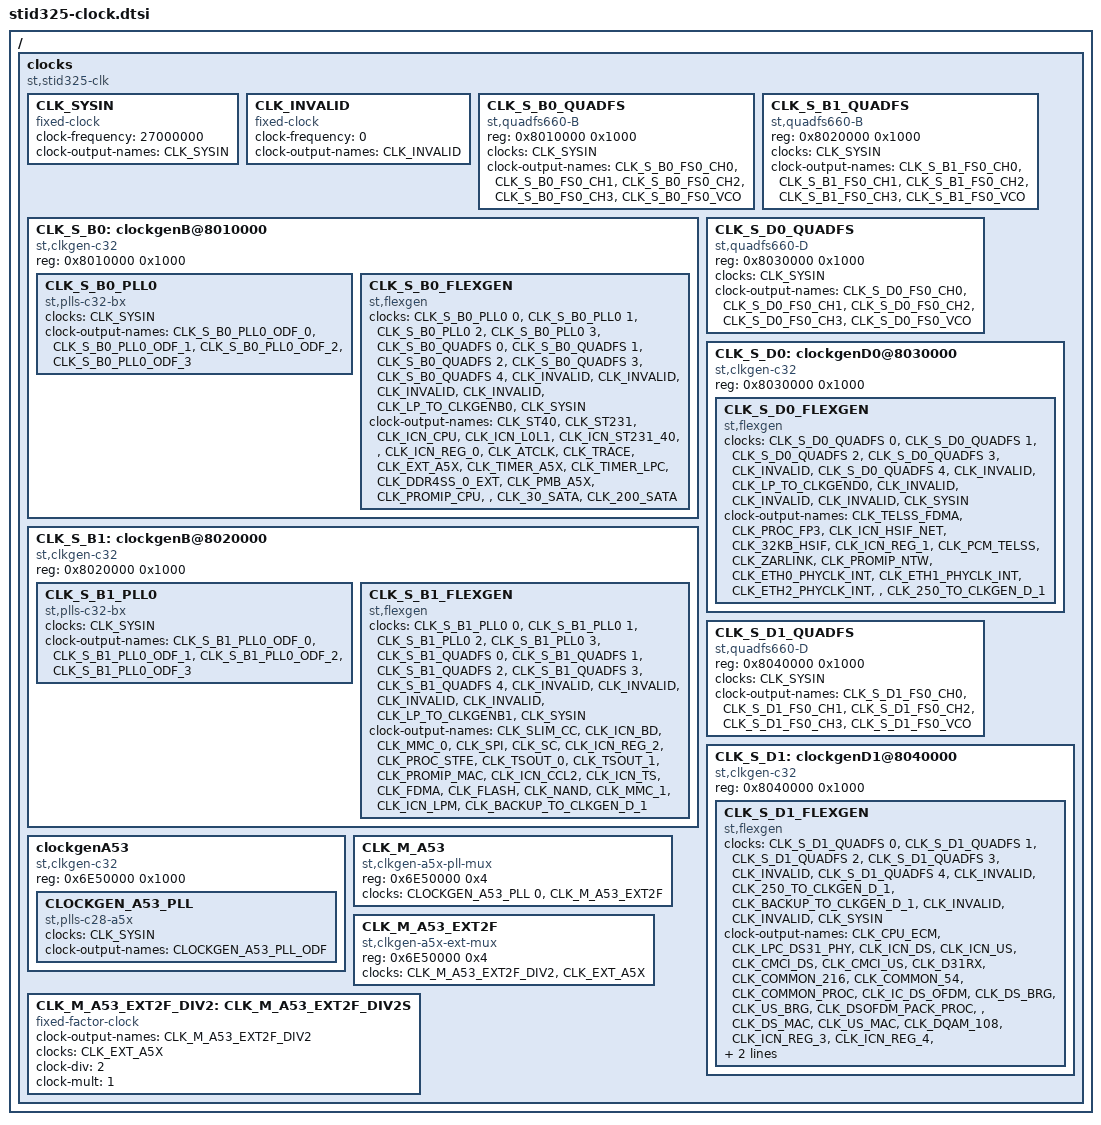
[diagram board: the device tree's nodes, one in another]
/*
 * Copyright (C) 2015 STMicroelectronics R&D Limited
 * Author: Giuseppe Condorelli <giuseppe.condorelli@st.com>
 *
 * This program is free software; you can redistribute it and/or modify
 * it under the terms of the GNU General Public License version 2 as
 * published by the Free Software Foundation.
 */

#include "stid325-clk-refs.h"

/ {
	clocks {
		#address-cells = <1>;
		#size-cells = <1>;
		ranges;
		compatible = "st,stid325-clk", "simple-bus";

		/*
		 * Fixed 27MHz oscillator inputs to SoC
		 */
		CLK_SYSIN: CLK_SYSIN {
			#clock-cells = <0>;
			compatible = "fixed-clock";
			clock-frequency = <27000000>;
			clock-output-names = "CLK_SYSIN";
		};

		/*
		 * Fixed clock added to act as parent for flexigen parents
		 * for unused values in the multiplexer registers
		 */
		CLK_INVALID: CLK_INVALID {
			#clock-cells = <0>;
			compatible = "fixed-clock";
			clock-frequency = <0>;
			clock-output-names = "CLK_INVALID";
		};

		CLK_S_B0_QUADFS: CLK_S_B0_QUADFS {
			compatible = "st,quadfs660-B", "st,quadfs";
			reg = <0x8010000 0x1000>;

			#clock-cells = <1>;
			clocks = <&CLK_SYSIN>;
			clock-output-names = "CLK_S_B0_FS0_CH0",
					     "CLK_S_B0_FS0_CH1",
					     "CLK_S_B0_FS0_CH2",
					     "CLK_S_B0_FS0_CH3",
					     "CLK_S_B0_FS0_VCO";
		};

		CLK_S_B0: clockgenB@8010000 {
			compatible = "st,clkgen-c32";
			reg = <0x8010000 0x1000>;

			CLK_S_B0_PLL0: CLK_S_B0_PLL0 {
				compatible = "st,plls-c32-bx", "st,clkgen-plls-c32";

				#clock-cells = <1>;
				clocks = <&CLK_SYSIN>;
				clock-output-names = "CLK_S_B0_PLL0_ODF_0",
						     "CLK_S_B0_PLL0_ODF_1",
						     "CLK_S_B0_PLL0_ODF_2",
						     "CLK_S_B0_PLL0_ODF_3";
			};

			CLK_S_B0_FLEXGEN: CLK_S_B0_FLEXGEN {
				compatible = "st,flexgen";

				#clock-cells = <1>;

				clocks = <&CLK_S_B0_PLL0 0>,
					 <&CLK_S_B0_PLL0 1>,
					 <&CLK_S_B0_PLL0 2>,
					 <&CLK_S_B0_PLL0 3>,
					 <&CLK_S_B0_QUADFS 0>,
					 <&CLK_S_B0_QUADFS 1>,
					 <&CLK_S_B0_QUADFS 2>,
					 <&CLK_S_B0_QUADFS 3>,
					 <&CLK_S_B0_QUADFS 4>,
					 <&CLK_INVALID>,
					 <&CLK_INVALID>,
					 <&CLK_INVALID>,
					 <&CLK_INVALID>,
					 <&CLK_LP_TO_CLKGENB0>,
					 <&CLK_SYSIN>;

				clock-output-names = "CLK_ST40",
						     "CLK_ST231",
						     "CLK_ICN_CPU",
						     "CLK_ICN_L0L1",
						     "CLK_ICN_ST231_40",
						     "",
						     "CLK_ICN_REG_0",
						     "CLK_ATCLK",
						     "CLK_TRACE",
						     "CLK_EXT_A5X",
						     "CLK_TIMER_A5X",
						     "CLK_TIMER_LPC",
						     "CLK_DDR4SS_0_EXT",
						     "CLK_PMB_A5X",
						     "CLK_PROMIP_CPU",
						     "",
						     "CLK_30_SATA",
						     "CLK_200_SATA";
			};
		};

		CLK_S_B1_QUADFS: CLK_S_B1_QUADFS {
			compatible = "st,quadfs660-B", "st,quadfs";
			reg = <0x8020000 0x1000>;

			#clock-cells = <1>;
			clocks = <&CLK_SYSIN>;
			clock-output-names = "CLK_S_B1_FS0_CH0",
					     "CLK_S_B1_FS0_CH1",
					     "CLK_S_B1_FS0_CH2",
					     "CLK_S_B1_FS0_CH3",
					     "CLK_S_B1_FS0_VCO";
		};

		CLK_S_B1: clockgenB@8020000 {
			compatible = "st,clkgen-c32";
			reg = <0x8020000 0x1000>;

			CLK_S_B1_PLL0: CLK_S_B1_PLL0 {
				compatible = "st,plls-c32-bx", "st,clkgen-plls-c32";

				#clock-cells = <1>;
				clocks = <&CLK_SYSIN>;
				clock-output-names = "CLK_S_B1_PLL0_ODF_0",
						     "CLK_S_B1_PLL0_ODF_1",
						     "CLK_S_B1_PLL0_ODF_2",
						     "CLK_S_B1_PLL0_ODF_3";
			};

			CLK_S_B1_FLEXGEN: CLK_S_B1_FLEXGEN {
				compatible = "st,flexgen";

				#clock-cells = <1>;

				clocks = <&CLK_S_B1_PLL0 0>,
					 <&CLK_S_B1_PLL0 1>,
					 <&CLK_S_B1_PLL0 2>,
					 <&CLK_S_B1_PLL0 3>,
					 <&CLK_S_B1_QUADFS 0>,
					 <&CLK_S_B1_QUADFS 1>,
					 <&CLK_S_B1_QUADFS 2>,
					 <&CLK_S_B1_QUADFS 3>,
					 <&CLK_S_B1_QUADFS 4>,
					 <&CLK_INVALID>,
					 <&CLK_INVALID>,
					 <&CLK_INVALID>,
					 <&CLK_INVALID>,
					 <&CLK_LP_TO_CLKGENB1>,
					 <&CLK_SYSIN>;

				clock-output-names = "CLK_SLIM_CC",
						     "CLK_ICN_BD",
						     "CLK_MMC_0",
						     "CLK_SPI",
						     "CLK_SC",
						     "CLK_ICN_REG_2",
						     "CLK_PROC_STFE",
						     "CLK_TSOUT_0",
						     "CLK_TSOUT_1",
						     "CLK_PROMIP_MAC",
						     "CLK_ICN_CCL2",
						     "CLK_ICN_TS",
						     "CLK_FDMA",
						     "CLK_FLASH",
						     "CLK_NAND",
						     "CLK_MMC_1",
						     "CLK_ICN_LPM",
						     "CLK_BACKUP_TO_CLKGEN_D_1";
			};
		};

		CLK_S_D0_QUADFS: CLK_S_D0_QUADFS {
			compatible = "st,quadfs660-D", "st,quadfs";
			reg = <0x8030000 0x1000>;

			#clock-cells = <1>;
			clocks = <&CLK_SYSIN>;
			clock-output-names = "CLK_S_D0_FS0_CH0",
					     "CLK_S_D0_FS0_CH1",
					     "CLK_S_D0_FS0_CH2",
					     "CLK_S_D0_FS0_CH3",
					     "CLK_S_D0_FS0_VCO";
		};

		CLK_S_D0: clockgenD0@8030000 {
			compatible = "st,clkgen-c32";
			reg = <0x8030000 0x1000>;

			CLK_S_D0_FLEXGEN: CLK_S_D0_FLEXGEN {
				compatible = "st,flexgen";
				#clock-cells = <1>;

				clocks = <&CLK_S_D0_QUADFS 0>,
					 <&CLK_S_D0_QUADFS 1>,
					 <&CLK_S_D0_QUADFS 2>,
					 <&CLK_S_D0_QUADFS 3>,
					 <&CLK_INVALID>,
					 <&CLK_S_D0_QUADFS 4>,
					 <&CLK_INVALID>,
					 <&CLK_LP_TO_CLKGEND0>,
					 <&CLK_INVALID>,
					 <&CLK_INVALID>,
					 <&CLK_INVALID>,
					 <&CLK_SYSIN>;

				clock-output-names = "CLK_TELSS_FDMA",
						     "CLK_PROC_FP3",
						     "CLK_ICN_HSIF_NET",
						     "CLK_32KB_HSIF",
						     "CLK_ICN_REG_1",
						     "CLK_PCM_TELSS",
						     "CLK_ZARLINK",
						     "CLK_PROMIP_NTW",
						     "CLK_ETH0_PHYCLK_INT",
						     "CLK_ETH1_PHYCLK_INT",
						     "CLK_ETH2_PHYCLK_INT",
						     "",
						     "CLK_250_TO_CLKGEN_D_1";
			};
		};

		CLK_S_D1_QUADFS: CLK_S_D1_QUADFS {
			compatible = "st,quadfs660-D", "st,quadfs";
			reg = <0x8040000 0x1000>;

			#clock-cells = <1>;
			clocks = <&CLK_SYSIN>;
			clock-output-names = "CLK_S_D1_FS0_CH0",
					     "CLK_S_D1_FS0_CH1",
					     "CLK_S_D1_FS0_CH2",
					     "CLK_S_D1_FS0_CH3",
					     "CLK_S_D1_FS0_VCO";
		};

		CLK_S_D1: clockgenD1@8040000 {
			compatible = "st,clkgen-c32";
			reg = <0x8040000 0x1000>;

			CLK_S_D1_FLEXGEN: CLK_S_D1_FLEXGEN {
				compatible = "st,flexgen";
				#clock-cells = <1>;

				clocks = <&CLK_S_D1_QUADFS 0>,
					 <&CLK_S_D1_QUADFS 1>,
					 <&CLK_S_D1_QUADFS 2>,
					 <&CLK_S_D1_QUADFS 3>,
					 <&CLK_INVALID>,
					 <&CLK_S_D1_QUADFS 4>,
					 <&CLK_INVALID>,
					 <&CLK_250_TO_CLKGEN_D_1>,
					 <&CLK_BACKUP_TO_CLKGEN_D_1>,
					 <&CLK_INVALID>,
					 <&CLK_INVALID>,
					 <&CLK_SYSIN>;

				clock-output-names = "CLK_CPU_ECM",
						     "CLK_LPC_DS31_PHY",
						     "CLK_ICN_DS",
						     "CLK_ICN_US",
						     "CLK_CMCI_DS",
						     "CLK_CMCI_US",
						     "CLK_D31RX",
						     "CLK_COMMON_216",
						     "CLK_COMMON_54",
						     "CLK_COMMON_PROC",
						     "CLK_IC_DS_OFDM",
						     "CLK_DS_BRG",
						     "CLK_US_BRG",
						     "CLK_DSOFDM_PACK_PROC",
						     "",
						     "CLK_DS_MAC",
						     "CLK_US_MAC",
						     "CLK_DQAM_108",
						     "CLK_ICN_REG_3",
						     "CLK_ICN_REG_4",
						     "CLK_LP_TO_CLKGENB0",
						     "CLK_LP_TO_CLKGENB1",
						     "CLK_LP_TO_CLKGEND0";
			};
		};

		/*
		 * A53 PLL.
		 *
		 */
		clockgenA53 {
			compatible = "st,clkgen-c32";
			reg = <0x6E50000 0x1000>;

			CLOCKGEN_A53_PLL: CLOCKGEN_A53_PLL {
				compatible = "st,plls-c28-a5x", "st,clkgen-plls-c32";

				#clock-cells = <1>;
				clocks = <&CLK_SYSIN>;
				clock-output-names = "CLOCKGEN_A53_PLL_ODF";
			};
		};

		/*
		 * ARM CPU related clocks.
		 */
		CLK_M_A53: CLK_M_A53 {
			compatible = "st,clkgen-a5x-pll-mux", "st,clkgen-mux";
			#clock-cells = <0>;
			reg = <0x6E50000 0x4>;
			clocks = <&CLOCKGEN_A53_PLL 0>,
				 <&CLK_M_A53_EXT2F>;
		};

		CLK_M_A53_EXT2F: CLK_M_A53_EXT2F {
			compatible = "st,clkgen-a5x-ext-mux", "st,clkgen-mux";
			#clock-cells = <0>;
			reg = <0x6E50000 0x4>;
			clocks = <&CLK_M_A53_EXT2F_DIV2>,
				 <&CLK_EXT_A5X>;
		};

		CLK_M_A53_EXT2F_DIV2: CLK_M_A53_EXT2F_DIV2S {
			compatible = "fixed-factor-clock";

			#clock-cells = <0>;
			clock-output-names = "CLK_M_A53_EXT2F_DIV2";
			clocks = <&CLK_EXT_A5X>;
			clock-div = <2>;
			clock-mult = <1>;
		};
	};
};
